# TMS320F280049 register map
Vendor: Texas Instruments; Series: C2000 F28004x; File version: 0.2.0-generated
Registers are 16-bit, read-write, reset 0x0 unless marked. A register's access mark holds for its fields unless they carry their own. Offsets are from the block's base; [hi:lo] are bit positions.

## FSIRXAREGS — FSI RX Registers
Base 0x0000CD00
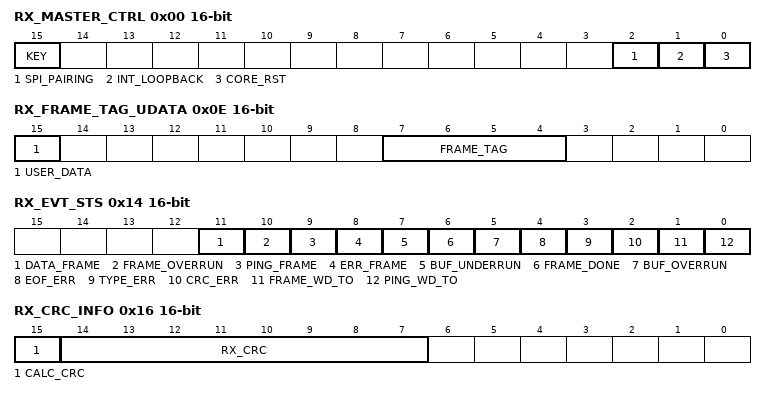
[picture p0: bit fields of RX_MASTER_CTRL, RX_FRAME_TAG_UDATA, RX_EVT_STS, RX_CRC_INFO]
0x00 RX_MASTER_CTRL — Receive master control register
  [15] KEY — Write Key
  [2] SPI_PAIRING — Clock Pairing for SPI-like Behaviour
  [1] INT_LOOPBACK — Internal Loopback Enable
  [0] CORE_RST — Receiver Main Core Reset
0x08 RX_OPER_CTRL — Receive operation control register
  [8] PING_WD_RST_MODE — Ping Watchdog Timeout Mode Select
  [7] ECC_SEL — ECC Data Width Select
  [9:6] N_WORDS — Number of Words to be Received
  [2] SPI_MODE — SPI Mode Enable
  [2:1] DATA_WIDTH — Receive Data Width Select
0x0C RX_FRAME_INFO — Receive frame control register
  [6:3] FRAME_TYPE — Received Frame Type
0x0E RX_FRAME_TAG_UDATA — Receive frame tag and user data register
  [15] USER_DATA — Received User Data
  [7:4] FRAME_TAG — Received Frame Tag
0x10 RX_DMA_CTRL — Receive DMA event control register
  [0] DMA_EVT_EN — DMA Event Enable
0x14 RX_EVT_STS — Receive event and error status flag register
  [11] DATA_FRAME — Data Frame Received Flag
  [10] FRAME_OVERRUN — Frame Overrun Flag
  [9] PING_FRAME — Ping Frame Received Flag
  [8] ERR_FRAME — Error Frame Received Flag
  [7] BUF_UNDERRUN — Receive Buffer Underrun Flag
  [6] FRAME_DONE — Frame Done Flag
  [5] BUF_OVERRUN — Receive Buffer Overrun Flag
  [4] EOF_ERR — End-of-Frame Error Flag
  [3] TYPE_ERR — Frame Type Error Flag
  [2] CRC_ERR — CRC Error Flag
  [1] FRAME_WD_TO — Frame Watchdog Timeout Flag.
  [0] PING_WD_TO — Ping Watchdog Timeout Flag
0x16 RX_CRC_INFO — Receive CRC info of received and computed CRC
  [15] CALC_CRC — Hardware Calculated CRC
  [14:7] RX_CRC — Received CRC Value
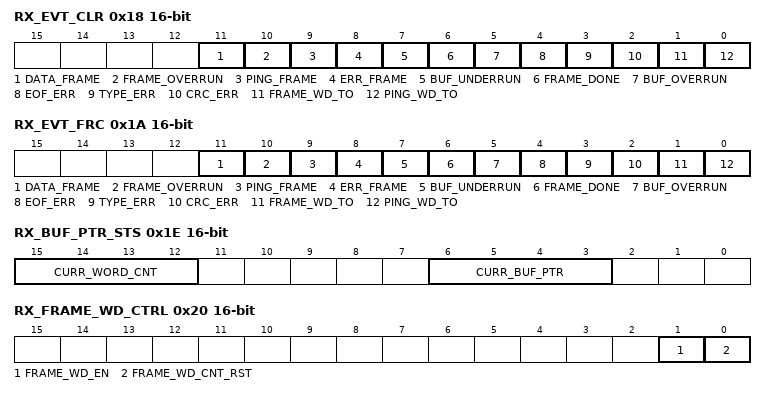
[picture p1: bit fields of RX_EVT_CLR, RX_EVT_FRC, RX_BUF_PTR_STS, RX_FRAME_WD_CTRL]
0x18 RX_EVT_CLR — Receive event and error clear register
  [11] DATA_FRAME — Data Frame Received Flag Clear
  [10] FRAME_OVERRUN — Frame Overrun Flag Clear
  [9] PING_FRAME — PING Frame Received Flag Clear
  [8] ERR_FRAME — Error Frame Received Flag Clear
  [7] BUF_UNDERRUN — Receive Buffer Underrun Flag Clear
  [6] FRAME_DONE — Frame Done Flag Clear
  [5] BUF_OVERRUN — Receive Buffer Overrun Flag Clear
  [4] EOF_ERR — End-of-Frame Error Flag Clear
  [3] TYPE_ERR — Frame Type Error Flag Clear
  [2] CRC_ERR — CRC Error Flag Clear
  [1] FRAME_WD_TO — Frame Watchdog Timeout Flag Clear
  [0] PING_WD_TO — Ping Watchdog Timeout Flag Clear
0x1A RX_EVT_FRC — Receive event and error flag force register
  [11] DATA_FRAME — Data Frame Received Flag Force
  [10] FRAME_OVERRUN — Frame Overrun Flag Force
  [9] PING_FRAME — Ping Frame Received Flag Force
  [8] ERR_FRAME — Error Frame Received Flag Force
  [7] BUF_UNDERRUN — Receive Buffer Underrun Flag Force
  [6] FRAME_DONE — Frame Done Flag Force
  [5] BUF_OVERRUN — Receive Buffer Overrun Flag Force
  [4] EOF_ERR — End-of-Frame Error Flag Force
  [3] TYPE_ERR — Frame Type Error Flag Force
  [2] CRC_ERR — CRC Error Flag Force
  [1] FRAME_WD_TO — Frame Watchdog Timeout Flag Force
  [0] PING_WD_TO — Ping Watchdog Timeout Flag Force
0x1C RX_BUF_PTR_LOAD — Receive buffer pointer load register
  [6:3] BUF_PTR_LOAD — Load value for receive buffer pointer
0x1E RX_BUF_PTR_STS — Receive buffer pointer status register
  [15:12] CURR_WORD_CNT — Available Words in Buffer
  [6:3] CURR_BUF_PTR — Current Buffer Pointer Index
0x20 RX_FRAME_WD_CTRL — Receive frame watchdog control register
  [1] FRAME_WD_EN — Frame Watchdog Counter Enable
  [0] FRAME_WD_CNT_RST — Frame Watchdog Counter Reset
0x24 RX_FRAME_WD_REF 32-bit — Receive frame watchdog counter reference
  [31] FRAME_WD_REF — Frame Watchdog Counter Reference Value
0x28 RX_FRAME_WD_CNT 32-bit — Receive frame watchdog current count
  [31] FRAME_WD_CNT — Frame Watchdog Counter Value
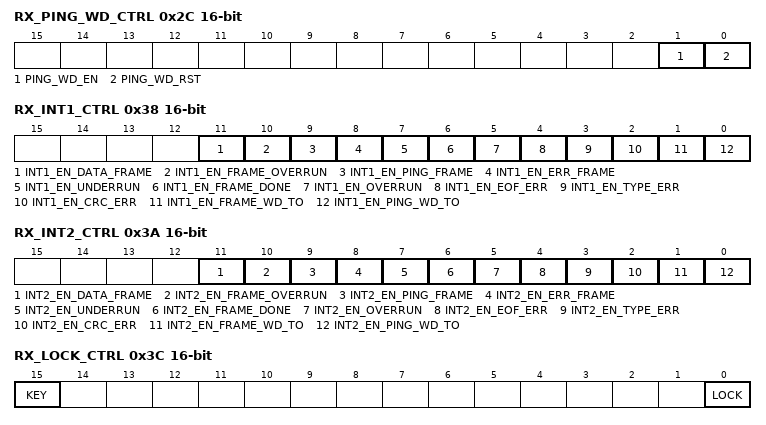
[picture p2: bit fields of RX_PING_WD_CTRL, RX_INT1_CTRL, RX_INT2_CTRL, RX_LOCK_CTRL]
0x2C RX_PING_WD_CTRL — Receive ping watchdog control register
  [1] PING_WD_EN — Ping Watchdog Counter Enable
  [0] PING_WD_RST — Ping Watchdog Counter Reset
0x2E RX_PING_TAG — Receive ping tag register
  [7:4] PING_TAG — Ping Frame Tag
0x30 RX_PING_WD_REF 32-bit — Receive ping watchdog counter reference
  [31] PING_WD_REF — PING Watchdog Counter Reference Value
0x34 RX_PING_WD_CNT 32-bit — Receive pingwatchdog current count
  [31] PING_WD_CNT — Ping Watchdog Counter Value
0x38 RX_INT1_CTRL — Receive interrupt control register for RX_INT1
  [11] INT1_EN_DATA_FRAME — Enable Data Frame Received Interrupt to INT1
  [10] INT1_EN_FRAME_OVERRUN — Enable Frame Overrun Interrupt to INT1
  [9] INT1_EN_PING_FRAME — Enable Ping Frame Received Interrupt to INT1
  [8] INT1_EN_ERR_FRAME — Enable Error Frame Received Interrupt to INT1
  [7] INT1_EN_UNDERRUN — Enable Buffer Underrun Interrupt to INT1
  [6] INT1_EN_FRAME_DONE — Enable Frame Done Interrupt to INT1
  [5] INT1_EN_OVERRUN — Enable Receive Buffer Overrun Interrupt to INT1
  [4] INT1_EN_EOF_ERR — Enable End-of-Frame Error Interrupt to INT1
  [3] INT1_EN_TYPE_ERR — Enable Frame Type Error Interrupt to INT1
  [2] INT1_EN_CRC_ERR — Enable CRC Error Interrupt to INT1
  [1] INT1_EN_FRAME_WD_TO — Enable Frame Watchdog Timeout Interrupt to INT1
  [0] INT1_EN_PING_WD_TO — Enable Ping Watchdog Timeout Interrupt to INT1
0x3A RX_INT2_CTRL — Receive interrupt control register for RX_INT2
  [11] INT2_EN_DATA_FRAME — Enable Data Frame Received Interrupt to INT2
  [10] INT2_EN_FRAME_OVERRUN — Enable Frame Overrun Interrupt to INT2
  [9] INT2_EN_PING_FRAME — Enable Ping Frame Received Interrupt to INT2
  [8] INT2_EN_ERR_FRAME — Enable Error Frame Received Interrupt to INT2
  [7] INT2_EN_UNDERRUN — Enable Buffer Underrun Interrupt to INT2
  [6] INT2_EN_FRAME_DONE — Enable Frame Done Interrupt to INT2
  [5] INT2_EN_OVERRUN — Enable Buffer Overrun Interrupt to INT2
  [4] INT2_EN_EOF_ERR — Enable End-of-Frame Error Interrupt to INT2
  [3] INT2_EN_TYPE_ERR — Enable Frame Type Error Interrupt to INT2
  [2] INT2_EN_CRC_ERR — Enable CRC Errror Interrupt to INT2
  [1] INT2_EN_FRAME_WD_TO — Enable Frame Watchdog Timeout Interrupt to INT2
  [0] INT2_EN_PING_WD_TO — Enable Ping Watchdog Timeout Interrupt to INT2
0x3C RX_LOCK_CTRL — Receive lock control register
  [15] KEY — Write Key
  [0] LOCK — Control Register Lock Enable
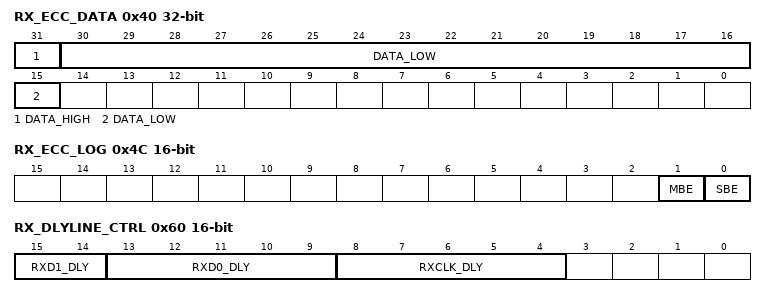
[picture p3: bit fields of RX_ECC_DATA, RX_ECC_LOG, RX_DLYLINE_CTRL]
0x40 RX_ECC_DATA 32-bit — Receive ECC data register
  [31] DATA_HIGH — ECC Data Upper 16 Bits
  [30:15] DATA_LOW — ECC Data Lower 16 Bits
0x44 RX_ECC_VAL — Receive ECC value register
  [12:6] ECC_VAL — Computed ECC Value
0x48 RX_ECC_SEC_DATA 32-bit — Receive ECC corrected data register
  [31] SEC_DATA — ECC Single Error Corrected Data
0x4C RX_ECC_LOG — Receive ECC log and status register
  [1] MBE — Multiple Bit Errors Detected
  [0] SBE — Single Bit Error Detected
0x60 RX_DLYLINE_CTRL — Receive delay line control register
  [15:14] RXD1_DLY — Delay Line Tap Select for RXD1
  [13:9] RXD0_DLY — Delay Line Tap Select for RXD0
  [8:4] RXCLK_DLY — Delay Line Tap Select for RXCLK
0x70 RX_VIS_1 32-bit — Receive debug visibility register 1
  [3] RX_CORE_STS — Receiver Core Status
0x80 RX_BUF_BASE — Base address for receive data buffer
  [15] BASE_ADDRESS — Receive Data Buffer Base Address
